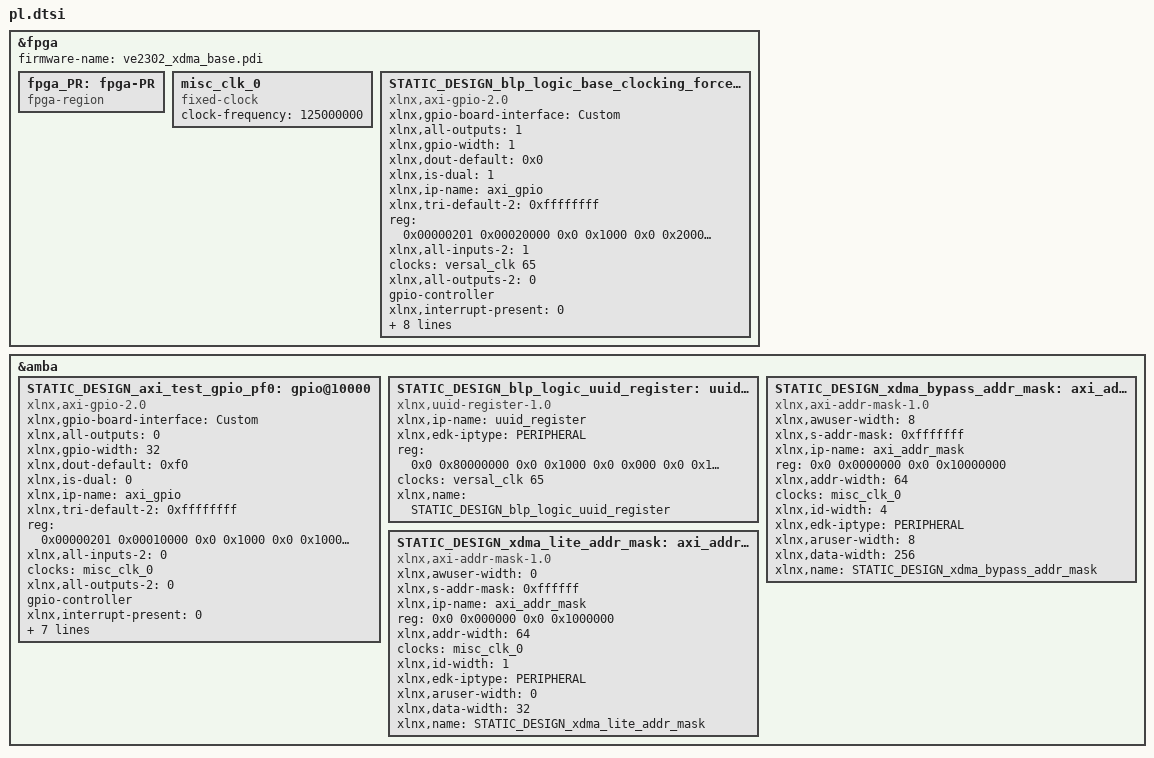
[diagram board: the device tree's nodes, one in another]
/dts-v1/;
/plugin/;
&fpga {
	firmware-name = "ve2302_xdma_base.pdi";
	fpga_PR: fpga-PR {
		ranges;
		compatible = "fpga-region";
		#address-cells = <2>;
		#size-cells = <2>;
	};
	misc_clk_0: misc_clk_0 {
		compatible = "fixed-clock";
		clock-frequency = <125000000>;
		#clock-cells = <0>;
	};
	STATIC_DESIGN_blp_logic_base_clocking_force_reset_gpio: gpio@20000 {
		xlnx,gpio-board-interface = "Custom";
		compatible = "xlnx,axi-gpio-2.0" , "xlnx,xps-gpio-1.00.a";
		xlnx,all-outputs = <1>;
		#gpio-cells = <2>;
		xlnx,gpio-width = <1>;
		xlnx,dout-default = <0x0>;
		xlnx,is-dual = <1>;
		xlnx,ip-name = "axi_gpio";
		xlnx,tri-default-2 = <0xffffffff>;
		reg = <0x00000201 0x00020000 0x0 0x1000 0x0 0x20000 0x0 0x1000>;
		xlnx,all-inputs-2 = <1>;
		clocks = <&versal_clk 65>;
		xlnx,all-outputs-2 = <0>;
		gpio-controller;
		xlnx,interrupt-present = <0>;
		xlnx,gpio2-board-interface = "Custom";
		xlnx,edk-iptype = "PERIPHERAL";
		xlnx,dout-default-2 = <0x0>;
		xlnx,gpio2-width = <1>;
		clock-names = "s_axi_aclk";
		xlnx,tri-default = <0xffffffff>;
		xlnx,name = "STATIC_DESIGN_blp_logic_base_clocking_force_reset_gpio";
		xlnx,all-inputs = <0>;
	};
};

&amba {
	STATIC_DESIGN_axi_test_gpio_pf0: gpio@10000 {
		xlnx,gpio-board-interface = "Custom";
		compatible = "xlnx,axi-gpio-2.0" , "xlnx,xps-gpio-1.00.a";
		xlnx,all-outputs = <0>;
		#gpio-cells = <2>;
		xlnx,gpio-width = <32>;
		xlnx,dout-default = <0xf0>;
		xlnx,is-dual = <0>;
		xlnx,ip-name = "axi_gpio";
		xlnx,tri-default-2 = <0xffffffff>;
		reg = <0x00000201 0x00010000 0x0 0x1000 0x0 0x10000 0x0 0x1000>;
		xlnx,all-inputs-2 = <0>;
		clocks = <&misc_clk_0>;
		xlnx,all-outputs-2 = <0>;
		gpio-controller;
		xlnx,interrupt-present = <0>;
		xlnx,gpio2-board-interface = "Custom";
		xlnx,edk-iptype = "PERIPHERAL";
		xlnx,dout-default-2 = <0x0>;
		xlnx,gpio2-width = <32>;
		clock-names = "s_axi_aclk";
		xlnx,tri-default = <0xffffffff>;
		xlnx,name = "STATIC_DESIGN_axi_test_gpio_pf0";
		xlnx,all-inputs = <0>;
	};
	STATIC_DESIGN_blp_logic_uuid_register: uuid_register@0 {
		compatible = "xlnx,uuid-register-1.0";
		clock-names = "S_AXI_ACLK";
		xlnx,ip-name = "uuid_register";
		xlnx,edk-iptype = "PERIPHERAL";
		reg = <0x0 0x80000000 0x0 0x1000 0x0 0x000 0x0 0x1000>;
		clocks = <&versal_clk 65>;
		xlnx,name = "STATIC_DESIGN_blp_logic_uuid_register";
	};
	STATIC_DESIGN_xdma_bypass_addr_mask: axi_addr_mask@0 {
		compatible = "xlnx,axi-addr-mask-1.0";
		xlnx,awuser-width = <8>;
		xlnx,s-addr-mask = <0xfffffff>;
		xlnx,ip-name = "axi_addr_mask";
		reg = <0x0 0x0000000 0x0 0x10000000>;
		xlnx,addr-width = <64>;
		clocks = <&misc_clk_0>;
		xlnx,id-width = <4>;
		xlnx,edk-iptype = "PERIPHERAL";
		clock-names = "aclk";
		xlnx,aruser-width = <8>;
		xlnx,data-width = <256>;
		xlnx,name = "STATIC_DESIGN_xdma_bypass_addr_mask";
	};
	STATIC_DESIGN_xdma_lite_addr_mask: axi_addr_mask@1 {
		compatible = "xlnx,axi-addr-mask-1.0";
		xlnx,awuser-width = <0>;
		xlnx,s-addr-mask = <0xffffff>;
		xlnx,ip-name = "axi_addr_mask";
		reg = <0x0 0x000000 0x0 0x1000000>;
		xlnx,addr-width = <64>;
		clocks = <&misc_clk_0>;
		xlnx,id-width = <1>;
		xlnx,edk-iptype = "PERIPHERAL";
		clock-names = "aclk";
		xlnx,aruser-width = <0>;
		xlnx,data-width = <32>;
		xlnx,name = "STATIC_DESIGN_xdma_lite_addr_mask";
	};
};
